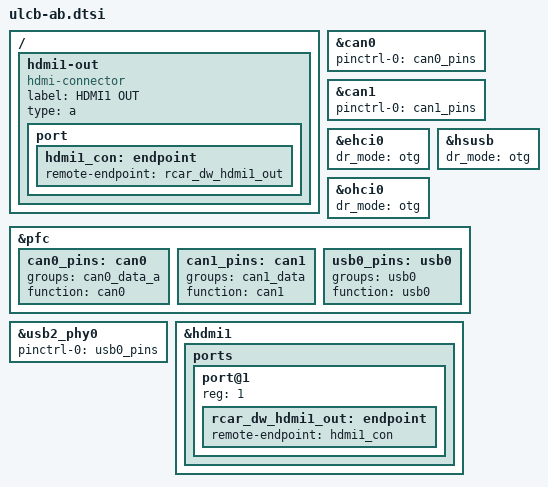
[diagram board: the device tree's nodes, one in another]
// SPDX-License-Identifier: GPL-2.0
/*
 * Device Tree Source for the Aosbox (CCPF Starter kit) board
 *
 * Copyright (C) 2017-2021 Renesas Electronics Corp.
 */

&can0 {
	pinctrl-0 = <&can0_pins>;
	pinctrl-names = "default";
	status = "okay";
};

&can1 {
	pinctrl-0 = <&can1_pins>;
	pinctrl-names = "default";
	status = "okay";
};

&ehci0 {
	dr_mode = "otg";
	status = "okay";
};

&hsusb {
	dr_mode = "otg";
	status = "okay";
};

&ohci0 {
	dr_mode = "otg";
	status = "okay";
};

&pfc {
	can0_pins: can0 {
		groups = "can0_data_a";
		function = "can0";
	};

	can1_pins: can1 {
		groups = "can1_data";
		function = "can1";
	};

	usb0_pins: usb0 {
		groups = "usb0";
		function = "usb0";
	};
};

&usb2_phy0 {
	pinctrl-0 = <&usb0_pins>;
	pinctrl-names = "default";

	status = "okay";
};

&hdmi1 {
	status = "okay";

	ports {
		port@1 {
			reg = <1>;
			rcar_dw_hdmi1_out: endpoint {
				remote-endpoint = <&hdmi1_con>;
			};
		};
	};
};

/ {
	hdmi1-out {
		compatible = "hdmi-connector";
        // TODO Do we need a label for hdmi0?
		label = "HDMI1 OUT";
		type = "a";

		port {
			hdmi1_con: endpoint {
	            remote-endpoint = <&rcar_dw_hdmi1_out>;
			};
		};
	};
};
